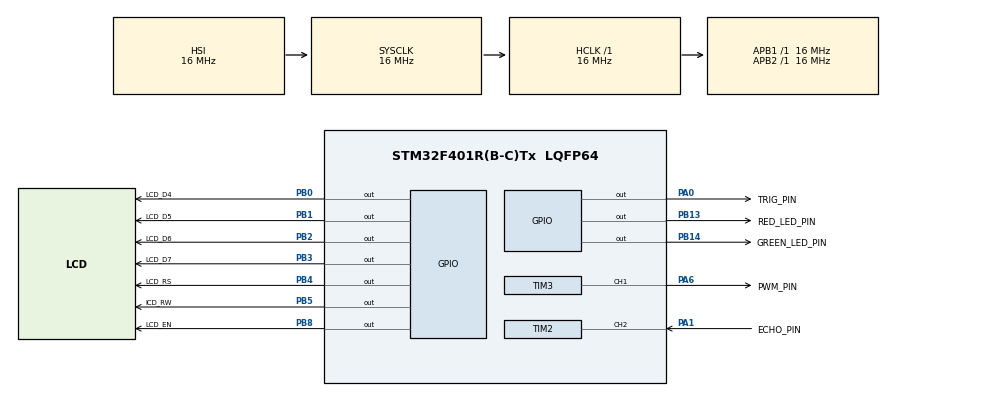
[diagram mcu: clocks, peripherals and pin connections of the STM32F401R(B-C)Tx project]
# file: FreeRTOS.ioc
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FREERTOS.Tasks01=defaultTask,0,128,StartDefaultTask,Default,NULL,Dynamic,NULL,NULL
Mcu.Family=STM32F4
Mcu.Name=STM32F401R(B-C)Tx
Mcu.Package=LQFP64
NVIC.PriorityGroup=NVIC_PRIORITYGROUP_4
NVIC.TIM2_IRQn=true\:5\:0\:false\:false\:true\:true\:true\:true\:true
PA0-WKUP.GPIO_Label=TRIG_PIN
PA0-WKUP.Signal=GPIO_Output
PA1.GPIO_Label=ECHO_PIN
PA1.Signal=S_TIM2_CH2
PA6.GPIO_Label=PWM_PIN
PA6.Signal=S_TIM3_CH1
PB0.GPIO_Label=LCD_D4
PB0.Signal=GPIO_Output
PB1.GPIO_Label=LCD_D5
PB1.Signal=GPIO_Output
PB13.GPIO_Label=RED_LED_PIN
PB13.Signal=GPIO_Output
PB14.GPIO_Label=GREEN_LED_PIN
PB14.Signal=GPIO_Output
PB2.GPIO_Label=LCD_D6
PB2.Signal=GPIO_Output
PB3.GPIO_Label=LCD_D7
PB3.Signal=GPIO_Output
PB4.GPIO_Label=LCD_RS
PB4.Signal=GPIO_Output
PB5.GPIO_Label=lCD_RW
PB5.Signal=GPIO_Output
PB8.GPIO_Label=LCD_EN
PB8.Signal=GPIO_Output
ProjectManager.HeapSize=0x200
ProjectManager.StackSize=0x400
ProjectManager.TargetToolchain=STM32CubeIDE
RCC.AHBFreq_Value=16000000
RCC.APB1Freq_Value=16000000
RCC.APB2Freq_Value=16000000
RCC.CortexFreq_Value=16000000
RCC.HSE_VALUE=25000000
RCC.HSI_VALUE=16000000
RCC.LSE_VALUE=32768
RCC.SYSCLKFreq_VALUE=16000000
RCC.VCOOutputFreq_Value=192000000
SH.S_TIM2_CH2.0=TIM2_CH2,Input_Capture2_from_TI2
SH.S_TIM3_CH1.0=TIM3_CH1,PWM Generation1 CH1
TIM2.AutoReloadPreload=TIM_AUTORELOAD_PRELOAD_ENABLE
TIM2.Channel-Input_Capture2_from_TI2=TIM_CHANNEL_2
TIM2.Prescaler=15
TIM3.AutoReloadPreload=TIM_AUTORELOAD_PRELOAD_ENABLE
TIM3.Channel-PWM\ Generation1\ CH1=TIM_CHANNEL_1
TIM3.Period=20000
TIM3.Prescaler=15
TIM3.Pulse-PWM\ Generation1\ CH1=1500
VP_FREERTOS_VS_CMSIS_V1.Mode=CMSIS_V1
VP_TIM2_VS_ClockSourceINT.Mode=Internal
VP_TIM3_VS_ClockSourceINT.Mode=Internal
board=custom

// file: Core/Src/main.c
/* USER CODE BEGIN Header */
/**
  ******************************************************************************
  * @file           : main.c
  * @brief          : Main program body
  ******************************************************************************
  * @attention
  *
  * Copyright (c) 2026 STMicroelectronics.
  * All rights reserved.
  *
  * This software is licensed under terms that can be found in the LICENSE file
  * in the root directory of this software component.
  * If no LICENSE file comes with this software, it is provided AS-IS.
  *
  ******************************************************************************
  */
/* USER CODE END Header */
#include "main.h"
#include "cmsis_os.h"

/* USER CODE BEGIN PTD */
#define LED_PORT GPIOB
#define RED_LED_PIN  GPIO_PIN_13
#define GREEN_LED_PIN GPIO_PIN_14
/* USER CODE END PTD */

TIM_HandleTypeDef htim2;
TIM_HandleTypeDef htim3;

osThreadId defaultTaskHandle;

void SystemClock_Config(void);
static void MX_GPIO_Init(void);
static void MX_TIM2_Init(void);
static void MX_TIM3_Init(void);
void StartDefaultTask(void const * argument);

int main(void)
{

  /* MCU Configuration--------------------------------------------------------*/

  /* Reset of all peripherals, Initializes the Flash interface and the Systick. */
  HAL_Init();

  /* Configure the system clock */
  SystemClock_Config();

  /* Initialize all configured peripherals */
  MX_GPIO_Init();
  MX_TIM2_Init();
  MX_TIM3_Init();
  /* USER CODE BEGIN 2 */
  /* 4. Create FreeRTOS tasks and queues */
   MX_FREERTOS_APP_Init();
   /* definition and creation of defaultTask
     osThreadDef(defaultTask, StartDefaultTask, osPriorityNormal, 0, 128);
     defaultTaskHandle = osThreadCreate(osThread(defaultTask), NULL);

        USER CODE BEGIN RTOS_THREADS */
     //Servo_Init(&htim3);
   /* 5. Start RTOS scheduler — never returns */
   vTaskStartScheduler();
  /* USER CODE END 2 */

  /* Create the thread(s) */
  /* definition and creation of defaultTask */
  osThreadDef(defaultTask, StartDefaultTask, osPriorityNormal, 0, 128);
  defaultTaskHandle = osThreadCreate(osThread(defaultTask), NULL);

  /* USER CODE BEGIN RTOS_THREADS */
     //Servo_Init(&htim3);
   /* 5. Start RTOS scheduler — never returns */
   vTaskStartScheduler();
  /* USER CODE END 2 */

  /* USER CODE BEGIN RTOS_MUTEX */
  /* add mutexes, ... */
  /* USER CODE END RTOS_MUTEX */

  /* USER CODE BEGIN RTOS_SEMAPHORES */
  /* add semaphores, ... */
  /* USER CODE END RTOS_SEMAPHORES */

  /* USER CODE BEGIN RTOS_TIMERS */
  /* start timers, add new ones, ... */
  /* USER CODE END RTOS_TIMERS */

  /* USER CODE BEGIN RTOS_QUEUES */
  /* add queues, ... */
  /* USER CODE END RTOS_QUEUES */

  /* Create the thread(s) */
  /* definition and creation of defaultTask */
//  osThreadDef(defaultTask, StartDefaultTask, osPriorityNormal, 0, 128);
 // defaultTaskHandle = osThreadCreate(osThread(defaultTask), NULL);

  /* USER CODE BEGIN RTOS_THREADS */
     //Servo_Init(&htim3);
   /* 5. Start RTOS scheduler — never returns */
   vTaskStartScheduler();
  /* USER CODE END 2 */

  /* USER CODE BEGIN RTOS_MUTEX */
  /* add mutexes, ... */
  /* USER CODE END RTOS_MUTEX */

  /* USER CODE BEGIN RTOS_SEMAPHORES */
  /* add semaphores, ... */
  /* USER CODE END RTOS_SEMAPHORES */

  /* USER CODE BEGIN RTOS_TIMERS */
  /* start timers, add new ones, ... */
  /* USER CODE END RTOS_TIMERS */

  /* USER CODE BEGIN RTOS_QUEUES */
  /* add queues, ... */
  /* USER CODE END RTOS_QUEUES */

  /* Create the thread(s) */

  /* add threads, ... */
  /* USER CODE END RTOS_THREADS */

  /* Start scheduler */
  osKernelStart();

  /* We should never get here as control is now taken by the scheduler */

  /* Infinite loop */
  while (1)
  {

  }
}

void SystemClock_Config(void)
{
  RCC_OscInitTypeDef RCC_OscInitStruct = {0};
  RCC_ClkInitTypeDef RCC_ClkInitStruct = {0};

  /** Configure the main internal regulator output voltage
  */
  __HAL_RCC_PWR_CLK_ENABLE();
  __HAL_PWR_VOLTAGESCALING_CONFIG(PWR_REGULATOR_VOLTAGE_SCALE2);

  /** Initializes the RCC Oscillators according to the specified parameters
  * in the RCC_OscInitTypeDef structure.
  */
  RCC_OscInitStruct.OscillatorType = RCC_OSCILLATORTYPE_HSI;
  RCC_OscInitStruct.HSIState = RCC_HSI_ON;
  RCC_OscInitStruct.HSICalibrationValue = RCC_HSICALIBRATION_DEFAULT;
  RCC_OscInitStruct.PLL.PLLState = RCC_PLL_NONE;
  if (HAL_RCC_OscConfig(&RCC_OscInitStruct) != HAL_OK)
  {
    Error_Handler();
  }

  /** Initializes the CPU, AHB and APB buses clocks
  */
  RCC_ClkInitStruct.ClockType = RCC_CLOCKTYPE_HCLK|RCC_CLOCKTYPE_SYSCLK
                              |RCC_CLOCKTYPE_PCLK1|RCC_CLOCKTYPE_PCLK2;
  RCC_ClkInitStruct.SYSCLKSource = RCC_SYSCLKSOURCE_HSI;
  RCC_ClkInitStruct.AHBCLKDivider = RCC_SYSCLK_DIV1;
  RCC_ClkInitStruct.APB1CLKDivider = RCC_HCLK_DIV1;
  RCC_ClkInitStruct.APB2CLKDivider = RCC_HCLK_DIV1;

  if (HAL_RCC_ClockConfig(&RCC_ClkInitStruct, FLASH_LATENCY_0) != HAL_OK)
  {
    Error_Handler();
  }
}

static void MX_TIM2_Init(void)
{

  TIM_ClockConfigTypeDef sClockSourceConfig = {0};
  TIM_MasterConfigTypeDef sMasterConfig = {0};
  TIM_IC_InitTypeDef sConfigIC = {0};

  htim2.Instance = TIM2;
  htim2.Init.Prescaler = 15;
  htim2.Init.CounterMode = TIM_COUNTERMODE_UP;
  htim2.Init.Period = 4294967295;
  htim2.Init.ClockDivision = TIM_CLOCKDIVISION_DIV1;
  htim2.Init.AutoReloadPreload = TIM_AUTORELOAD_PRELOAD_ENABLE;
  if (HAL_TIM_Base_Init(&htim2) != HAL_OK)
  {
    Error_Handler();
  }
  sClockSourceConfig.ClockSource = TIM_CLOCKSOURCE_INTERNAL;
  if (HAL_TIM_ConfigClockSource(&htim2, &sClockSourceConfig) != HAL_OK)
  {
    Error_Handler();
  }
  if (HAL_TIM_IC_Init(&htim2) != HAL_OK)
  {
    Error_Handler();
  }
  sMasterConfig.MasterOutputTrigger = TIM_TRGO_RESET;
  sMasterConfig.MasterSlaveMode = TIM_MASTERSLAVEMODE_DISABLE;
  if (HAL_TIMEx_MasterConfigSynchronization(&htim2, &sMasterConfig) != HAL_OK)
  {
    Error_Handler();
  }
  sConfigIC.ICPolarity = TIM_INPUTCHANNELPOLARITY_RISING;
  sConfigIC.ICSelection = TIM_ICSELECTION_DIRECTTI;
  sConfigIC.ICPrescaler = TIM_ICPSC_DIV1;
  sConfigIC.ICFilter = 0;
  if (HAL_TIM_IC_ConfigChannel(&htim2, &sConfigIC, TIM_CHANNEL_2) != HAL_OK)
  {
    Error_Handler();
  }

}

static void MX_TIM3_Init(void)
{

  TIM_ClockConfigTypeDef sClockSourceConfig = {0};
  TIM_MasterConfigTypeDef sMasterConfig = {0};
  TIM_OC_InitTypeDef sConfigOC = {0};

  htim3.Instance = TIM3;
  htim3.Init.Prescaler = 15;
  htim3.Init.CounterMode = TIM_COUNTERMODE_UP;
  htim3.Init.Period = 20000;
  htim3.Init.ClockDivision = TIM_CLOCKDIVISION_DIV1;
  htim3.Init.AutoReloadPreload = TIM_AUTORELOAD_PRELOAD_ENABLE;
  if (HAL_TIM_Base_Init(&htim3) != HAL_OK)
  {
    Error_Handler();
  }
  sClockSourceConfig.ClockSource = TIM_CLOCKSOURCE_INTERNAL;
  if (HAL_TIM_ConfigClockSource(&htim3, &sClockSourceConfig) != HAL_OK)
  {
    Error_Handler();
  }
  if (HAL_TIM_PWM_Init(&htim3) != HAL_OK)
  {
    Error_Handler();
  }
  sMasterConfig.MasterOutputTrigger = TIM_TRGO_RESET;
  sMasterConfig.MasterSlaveMode = TIM_MASTERSLAVEMODE_DISABLE;
  if (HAL_TIMEx_MasterConfigSynchronization(&htim3, &sMasterConfig) != HAL_OK)
  {
    Error_Handler();
  }
  sConfigOC.OCMode = TIM_OCMODE_PWM1;
  sConfigOC.Pulse = 1500;
  sConfigOC.OCPolarity = TIM_OCPOLARITY_HIGH;
  sConfigOC.OCFastMode = TIM_OCFAST_DISABLE;
  if (HAL_TIM_PWM_ConfigChannel(&htim3, &sConfigOC, TIM_CHANNEL_1) != HAL_OK)
  {
    Error_Handler();
  }
  HAL_TIM_MspPostInit(&htim3);

}

static void MX_GPIO_Init(void)
{
  GPIO_InitTypeDef GPIO_InitStruct = {0};

  /* GPIO Ports Clock Enable */
  __HAL_RCC_GPIOA_CLK_ENABLE();
  __HAL_RCC_GPIOB_CLK_ENABLE();

  /*Configure GPIO pin Output Level */
  HAL_GPIO_WritePin(TRIG_PIN_GPIO_Port, TRIG_PIN_Pin, GPIO_PIN_RESET);

  /*Configure GPIO pin Output Level */
  HAL_GPIO_WritePin(GPIOB, LCD_D4_Pin|LCD_D5_Pin|LCD_D6_Pin|RED_LED_PIN_Pin
                          |GREEN_LED_PIN_Pin|LCD_D7_Pin|LCD_RS_Pin|lCD_RW_Pin
                          |LCD_EN_Pin, GPIO_PIN_RESET);

  /*Configure GPIO pin : TRIG_PIN_Pin */
  GPIO_InitStruct.Pin = TRIG_PIN_Pin;
  GPIO_InitStruct.Mode = GPIO_MODE_OUTPUT_PP;
  GPIO_InitStruct.Pull = GPIO_NOPULL;
  GPIO_InitStruct.Speed = GPIO_SPEED_FREQ_LOW;
  HAL_GPIO_Init(TRIG_PIN_GPIO_Port, &GPIO_InitStruct);

  /*Configure GPIO pins : LCD_D4_Pin LCD_D5_Pin LCD_D6_Pin RED_LED_PIN_Pin
                           GREEN_LED_PIN_Pin LCD_D7_Pin LCD_RS_Pin lCD_RW_Pin
                           LCD_EN_Pin */
  GPIO_InitStruct.Pin = LCD_D4_Pin|LCD_D5_Pin|LCD_D6_Pin|RED_LED_PIN_Pin
                          |GREEN_LED_PIN_Pin|LCD_D7_Pin|LCD_RS_Pin|lCD_RW_Pin
                          |LCD_EN_Pin;
  GPIO_InitStruct.Mode = GPIO_MODE_OUTPUT_PP;
  GPIO_InitStruct.Pull = GPIO_NOPULL;
  GPIO_InitStruct.Speed = GPIO_SPEED_FREQ_LOW;
  HAL_GPIO_Init(GPIOB, &GPIO_InitStruct);

}

void StartDefaultTask(void const * argument)
{
  for(;;)
  {
    osDelay(1);
  }
}

void Error_Handler(void)
{
  __disable_irq();
  while (1)
  {
  }
}
